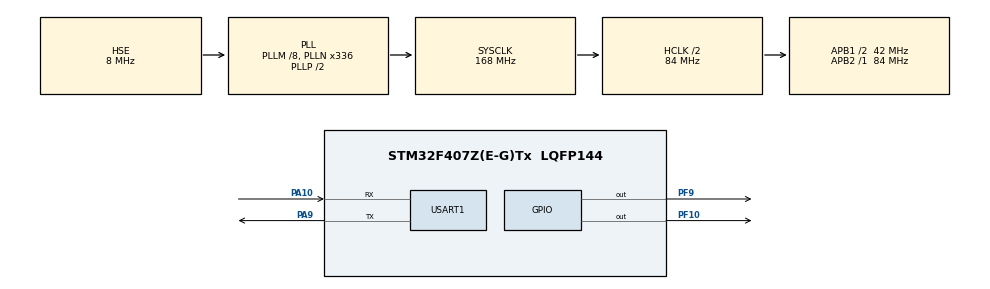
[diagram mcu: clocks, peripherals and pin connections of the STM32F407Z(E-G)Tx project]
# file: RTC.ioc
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Mcu.Family=STM32F4
Mcu.Name=STM32F407Z(E-G)Tx
Mcu.Package=LQFP144
NVIC.PriorityGroup=NVIC_PRIORITYGROUP_4
NVIC.RTC_Alarm_IRQn=true\:0\:0\:false\:false\:true\:true\:true
PA10.Mode=Asynchronous
PA10.Signal=USART1_RX
PA9.Mode=Asynchronous
PA9.Signal=USART1_TX
PC14-OSC32_IN.Mode=LSE-External-Oscillator
PC14-OSC32_IN.Signal=RCC_OSC32_IN
PC15-OSC32_OUT.Mode=LSE-External-Oscillator
PC15-OSC32_OUT.Signal=RCC_OSC32_OUT
PF10.Signal=GPIO_Output
PF9.Signal=GPIO_Output
PH0-OSC_IN.Mode=HSE-External-Oscillator
PH0-OSC_IN.Signal=RCC_OSC_IN
PH1-OSC_OUT.Mode=HSE-External-Oscillator
PH1-OSC_OUT.Signal=RCC_OSC_OUT
ProjectManager.HeapSize=0x200
ProjectManager.StackSize=0x400
ProjectManager.TargetToolchain=MDK-ARM V5.27
RCC.48MHZClocksFreq_Value=84000000
RCC.AHBCLKDivider=RCC_SYSCLK_DIV2
RCC.AHBFreq_Value=84000000
RCC.APB1CLKDivider=RCC_HCLK_DIV2
RCC.APB1Freq_Value=42000000
RCC.APB1TimFreq_Value=84000000
RCC.APB2Freq_Value=84000000
RCC.APB2TimFreq_Value=84000000
RCC.CortexFreq_Value=84000000
RCC.HCLKFreq_Value=84000000
RCC.HSE_VALUE=8000000
RCC.HSI_VALUE=16000000
RCC.PLLM=8
RCC.PLLN=336
RCC.PLLSourceVirtual=RCC_PLLSOURCE_HSE
RCC.RCC_RTC_Clock_Source=RCC_RTCCLKSOURCE_LSE
RCC.SYSCLKFreq_VALUE=168000000
RCC.SYSCLKSource=RCC_SYSCLKSOURCE_PLLCLK
RCC.VCOOutputFreq_Value=336000000
RTC.Alarm=RTC_ALARM_A
RTC.Hours=20
RTC.Hours_A=21
RTC.Minutes=59
RTC.Seconds=30
USART1.VirtualMode=VM_ASYNC
VP_RTC_VS_RTC_Activate.Mode=RTC_Enabled
VP_RTC_VS_RTC_Alarm_A_Intern.Mode=Alarm A
VP_RTC_VS_RTC_Calendar.Mode=RTC_Calendar
board=custom

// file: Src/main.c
/* USER CODE BEGIN Header */
/**
  ******************************************************************************
  * @file           : main.c
  * @brief          : Main program body
  ******************************************************************************
  * @attention
  *
  * <h2><center>&copy; Copyright (c) 2020 STMicroelectronics.
  * All rights reserved.</center></h2>
  *
  * This software component is licensed by ST under BSD 3-Clause license,
  * the "License"; You may not use this file except in compliance with the
  * License. You may obtain a copy of the License at:
  *                        opensource.org/licenses/BSD-3-Clause
  *
  ******************************************************************************
  */
/* USER CODE END Header */

#include "main.h"
#include "rtc.h"
#include "usart.h"
#include "gpio.h"

void SystemClock_Config(void);

/* USER CODE BEGIN 0 */
RTC_DateTypeDef GetData;  //��ȡ���ڽṹ��

RTC_TimeTypeDef GetTime;   //��ȡʱ��ṹ��

/* USER CODE END 0 */

int main(void)
{

  /* MCU Configuration--------------------------------------------------------*/

  /* Reset of all peripherals, Initializes the Flash interface and the Systick. */
  HAL_Init();

  /* Configure the system clock */
  SystemClock_Config();

  /* Initialize all configured peripherals */
  MX_GPIO_Init();
  MX_RTC_Init();
  MX_USART1_UART_Init();

  /* Infinite loop */
  while (1)
  {
	  /* Get the RTC current Time */
	  HAL_RTC_GetTime(&hrtc, &GetTime, RTC_FORMAT_BIN);
		/* Get the RTC current Date */
		HAL_RTC_GetDate(&hrtc, &GetData, RTC_FORMAT_BIN);

		/* Display date Format : yy/mm/dd */
		printf("%02d/%02d/%02d\r\n",2000 + GetData.Year, GetData.Month, GetData.Date);
		/* Display time Format : hh:mm:ss */
		printf("%02d:%02d:%02d\r\n",GetTime.Hours, GetTime.Minutes, GetTime.Seconds);

		printf("\r\n");

		HAL_Delay(1000);

  }
}

void SystemClock_Config(void)
{
  RCC_OscInitTypeDef RCC_OscInitStruct = {0};
  RCC_ClkInitTypeDef RCC_ClkInitStruct = {0};
  RCC_PeriphCLKInitTypeDef PeriphClkInitStruct = {0};

  /** Configure the main internal regulator output voltage
  */
  __HAL_RCC_PWR_CLK_ENABLE();
  __HAL_PWR_VOLTAGESCALING_CONFIG(PWR_REGULATOR_VOLTAGE_SCALE1);
  /** Initializes the CPU, AHB and APB busses clocks
  */
  RCC_OscInitStruct.OscillatorType = RCC_OSCILLATORTYPE_HSE|RCC_OSCILLATORTYPE_LSE;
  RCC_OscInitStruct.HSEState = RCC_HSE_ON;
  RCC_OscInitStruct.LSEState = RCC_LSE_ON;
  RCC_OscInitStruct.PLL.PLLState = RCC_PLL_ON;
  RCC_OscInitStruct.PLL.PLLSource = RCC_PLLSOURCE_HSE;
  RCC_OscInitStruct.PLL.PLLM = 8;
  RCC_OscInitStruct.PLL.PLLN = 336;
  RCC_OscInitStruct.PLL.PLLP = RCC_PLLP_DIV2;
  RCC_OscInitStruct.PLL.PLLQ = 4;
  if (HAL_RCC_OscConfig(&RCC_OscInitStruct) != HAL_OK)
  {
    Error_Handler();
  }
  /** Initializes the CPU, AHB and APB busses clocks
  */
  RCC_ClkInitStruct.ClockType = RCC_CLOCKTYPE_HCLK|RCC_CLOCKTYPE_SYSCLK
                              |RCC_CLOCKTYPE_PCLK1|RCC_CLOCKTYPE_PCLK2;
  RCC_ClkInitStruct.SYSCLKSource = RCC_SYSCLKSOURCE_PLLCLK;
  RCC_ClkInitStruct.AHBCLKDivider = RCC_SYSCLK_DIV2;
  RCC_ClkInitStruct.APB1CLKDivider = RCC_HCLK_DIV2;
  RCC_ClkInitStruct.APB2CLKDivider = RCC_HCLK_DIV1;

  if (HAL_RCC_ClockConfig(&RCC_ClkInitStruct, FLASH_LATENCY_2) != HAL_OK)
  {
    Error_Handler();
  }
  PeriphClkInitStruct.PeriphClockSelection = RCC_PERIPHCLK_RTC;
  PeriphClkInitStruct.RTCClockSelection = RCC_RTCCLKSOURCE_LSE;
  if (HAL_RCCEx_PeriphCLKConfig(&PeriphClkInitStruct) != HAL_OK)
  {
    Error_Handler();
  }
}

void Error_Handler(void)
{
}

/************************ (C) COPYRIGHT STMicroelectronics *****END OF FILE****/
